# Montana register map
Vendor: ONSemiconductor; Series: Montana Series; File version: 1.0
CPU: CM33 r0p4, little endian, MPU, FPU, 3 interrupt priority bits
Registers are 32-bit, read-write, reset 0x0 unless marked. A register's access mark holds for its fields unless they carry their own. Offsets are from the block's base; [hi:lo] are bit positions; {n}, {i} and the like mark numbered series.

## CRC — CRC Generator Control
Base 0x40001300
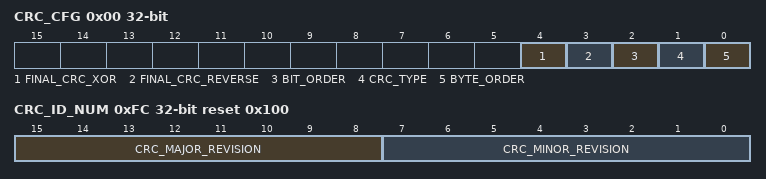
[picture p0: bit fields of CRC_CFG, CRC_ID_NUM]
0x00 CRC_CFG — CRC Generator Configuration Register
  [4] FINAL_CRC_XOR — Selects the final CRC XOR mode
    0=CRC_FINAL_XOR_STANDARD (Final CRC XOR is done according to the standard (CRC-CCITT: no XOR; CRC-32: XOR with 0xFFFFFFFF)); 1=CRC_FINAL_XOR_NON_STANDARD (Final CRC XOR is done in opposite of the standard)
  [3] FINAL_CRC_REVERSE — Selects the final CRC reversal mode
    0=CRC_FINAL_REVERSE_STANDARD (Final CRC reversal is done according to the standard (CRC-CCITT: normal; CRC-32 reversed)); 1=CRC_FINAL_REVERSE_NON_STANDARD (Final CRC reversal is done in opposite of the standard)
  [2] BIT_ORDER — Selects the bit order for bytes added to the CRC
    0=CRC_BIT_ORDER_STANDARD (Bit order is as defined by the standard (CRC-CCITT: normal; CRC-32 reversed)); 1=CRC_BIT_ORDER_NON_STANDARD (Bit order is opposite of the standard)
  [1] CRC_TYPE — Selects the CRC type
    0=CRC_CCITT (CRC-CCITT algorithm selected); 1=CRC_32 (CRC-32 (IEEE 802.3) algorithm selected)
  [0] BYTE_ORDER — Selects the endianness for bytes added to the CRC
    0=CRC_BIG_ENDIAN (Bytes are added to the CRC in big-endian order); 1=CRC_LITTLE_ENDIAN (Bytes are added to the CRC in little-endian order)
0x04 CRC_VALUE reset 0xFFFF — CRC Generator Current Value Register
  [31:0] CURRENT_CRC — CRC generator value: Write 0xFFFFFFF (32) or 0xFFFF (CCITT) to initialize the CRC, read provides the current CRC value.
    0xFFFF=CRC_CCITT_INIT_VALUE (Initial value for the CRC CCITT calculation); 0xFFFFFFFF=CRC_32_INIT_VALUE (Initial value for the CRC 32 calculation)
0x08 CRC_ADD_1 reset not defined — CRC Generator - Add 1 Bit
  [0] CRC_ADD_1 wo — Add 1 bit to the CRC calculation
0x0C CRC_ADD_8 reset not defined — CRC Generator - Add 1 Byte
  [7:0] CRC_ADD_8 wo — Add 1 byte (8 bits) to the CRC calculation
0x10 CRC_ADD_16 reset not defined — CRC Generator - Add 1 Half-word
  [15:0] CRC_ADD_16 wo — Add 1 half-word (16 bits) to the CRC calculation
0x14 CRC_ADD_24 reset not defined — CRC Generator - Add 3 Bytes
  [23:0] CRC_ADD_24 wo — Add 3 bytes (24 bits) to the CRC calculation
0x18 CRC_ADD_32 reset not defined — CRC Generator - Add 1 Word
  [31:0] CRC_ADD_32 wo — Add 1 word (32 bits) to the CRC calculation
0x1C CRC_FINAL ro — CRC Generator Final Value
  [31:0] FINAL_CRC — CRC generator final value: After XOR for CCITT or byte reversal for CRC-32
0xFC CRC_ID_NUM ro reset 0x100 — CRC ID number
  [15:8] CRC_MAJOR_REVISION — CRC Major Revision number
    1=CRC_MAJOR_REVISION (CRC revision 1.0)
  [7:0] CRC_MINOR_REVISION — CRC Minor Revision number
    0=CRC_MINOR_REVISION (CRC revision 1.0)

## ASCC — Asynchronous Clock Counter
Base 0x40001400
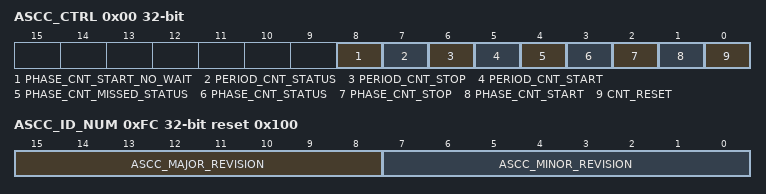
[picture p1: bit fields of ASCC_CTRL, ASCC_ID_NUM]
0x00 ASCC_CTRL (reset mask 0x98) — ASCC Control Register
  [8] PHASE_CNT_START_NO_WAIT wo — Start the asynchronous clock phase counter mechanism without waiting on a sync pulse
    1=PHASE_CNT_START_NO_WAIT (Reset PHASE_CNT and start the asynchronous clock phase counter mechanism without waiting on a sync pulse)
  [7] PERIOD_CNT_STATUS ro — Asynchronous clock period counter status
    0=PERIOD_CNT_IDLE (The asynchronous clock period counter mechanism is idle); 1=PERIOD_CNT_BUSY (The asynchronous clock period counter mechanism is busy)
  [6] PERIOD_CNT_STOP wo — Stop the asynchronous clock period counter mechanism
    1=PERIOD_CNT_STOP (Stop the asynchronous clock period counter mechanism)
  [5] PERIOD_CNT_START wo — Start the asynchronous clock period counter mechanism
    1=PERIOD_CNT_START (Reset PERIOD_CNT and start the asynchronous clock period counter mechanism)
  [4] PHASE_CNT_MISSED_STATUS ro — Asynchronous clock phase counter missed status
    0=PHASE_CNT_NORMAL (The asynchronous clock phase counter mechanism was not stopped due to a missed synchronization signal); 1=PHASE_CNT_MISSED (The asynchronous clock phase counter mechanism was stopped due to a missed synchronization signal)
  [3] PHASE_CNT_STATUS ro — Asynchronous clock phase counter status
    0=PHASE_CNT_IDLE (The asynchronous clock phase counter mechanism is idle); 1=PHASE_CNT_BUSY (The asynchronous clock phase counter mechanism is busy)
  [2] PHASE_CNT_STOP wo — Stop the asynchronous clock phase counter mechanism
    1=PHASE_CNT_STOP (Stop the asynchronous clock phase counter mechanism)
  [1] PHASE_CNT_START wo — Start the asynchronous clock phase counter mechanism and wait for sync pulse
    1=PHASE_CNT_START (Reset PHASE_CNT and start the asynchronous clock phase counter mechanism and wait on a sync pulse)
  [0] CNT_RESET wo — Reset asynchronous clock counter
    1=CNT_RESET (Reset asynchronous clock counter)
0x04 ASCC_CFG — ASCC Configuration Register
  [3:0] PERIODS_CFG — Defines over how many asynchronous clock periods the period counter measures
    0=ASCC_PERIODS_1 (Measure 1 asynchronous clock period); {v}=ASCC_PERIODS_{v+1} (Measure {v+1} asynchronous clock periods) (v=1..15)
0x08 ASCC_CNT ro — ASCC Counter Register
  [11:0] CNT — Asynchronous clock counter value
0x0C ASCC_PHASE_CNT — ASCC Phase Counter Register
  [15:0] PHASE_CNT — Asynchronous clock phase counter value
0x10 ASCC_PERIOD_CNT — ASCC Period Counter Register
  [15:0] PERIOD_CNT — Asynchronous clock period counter value
0xFC ASCC_ID_NUM ro reset 0x100 — ASCC ID number
  [15:8] ASCC_MAJOR_REVISION — ASCC Major Revision number
    1=ASCC_MAJOR_REVISION (ASCC revision 1.0)
  [7:0] ASCC_MINOR_REVISION — ASCC Minor Revision number
    0=ASCC_MINOR_REVISION (ASCC revision 1.0)
